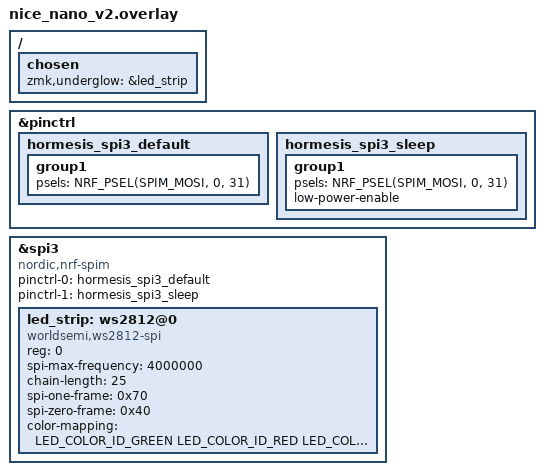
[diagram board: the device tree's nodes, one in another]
#include <dt-bindings/led/led.h>

&pinctrl {
    hormesis_spi3_default: hormesis_spi3_default {
        group1 {
            psels = <NRF_PSEL(SPIM_MOSI, 0, 31)>;
        };
    };

    hormesis_spi3_sleep: hormesis_spi3_sleep {
        group1 {
            psels = <NRF_PSEL(SPIM_MOSI, 0, 31)>;
            low-power-enable;
        };
    };
};

&spi3 {
    compatible = "nordic,nrf-spim";
    status = "okay";

    pinctrl-0 = <&hormesis_spi3_default>;
    pinctrl-1 = <&hormesis_spi3_sleep>;
    pinctrl-names = "default", "sleep";

    led_strip: ws2812@0 {
        compatible = "worldsemi,ws2812-spi";
        reg = <0>;
        spi-max-frequency = <4000000>;
        chain-length = <25>;
        spi-one-frame = <0x70>;
        spi-zero-frame = <0x40>;
        color-mapping = <
            LED_COLOR_ID_GREEN
            LED_COLOR_ID_RED
            LED_COLOR_ID_BLUE
        >;
    };
};

/ {
    chosen {
        zmk,underglow = &led_strip;
    };
};
